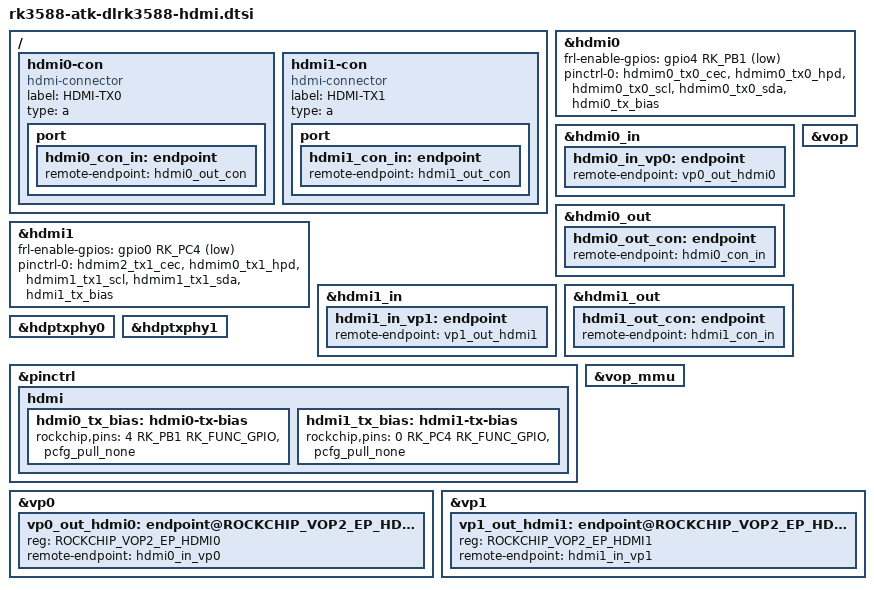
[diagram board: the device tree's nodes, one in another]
// SPDX-License-Identifier: (GPL-2.0+ OR MIT)
/*
 * ATK-DLRK3588 HDMI TX wiring, from the Alientek rk3588-atk-lcds.dtsi.
 * The vendor's enable-gpios controls the TMDS bias (high in TMDS mode,
 * low in FRL mode). Mainline models this as active-low frl-enable-gpios.
 */
#include <dt-bindings/soc/rockchip,vop2.h>

/ {
	hdmi0-con {
		compatible = "hdmi-connector";
		label = "HDMI-TX0";
		type = "a";

		port {
			hdmi0_con_in: endpoint {
				remote-endpoint = <&hdmi0_out_con>;
			};
		};
	};

	hdmi1-con {
		compatible = "hdmi-connector";
		label = "HDMI-TX1";
		type = "a";

		port {
			hdmi1_con_in: endpoint {
				remote-endpoint = <&hdmi1_out_con>;
			};
		};
	};
};

&hdmi0 {
	frl-enable-gpios = <&gpio4 RK_PB1 GPIO_ACTIVE_LOW>;
	pinctrl-0 = <&hdmim0_tx0_cec &hdmim0_tx0_hpd
		     &hdmim0_tx0_scl &hdmim0_tx0_sda &hdmi0_tx_bias>;
	status = "okay";
};

&hdmi0_in {
	hdmi0_in_vp0: endpoint {
		remote-endpoint = <&vp0_out_hdmi0>;
	};
};

&hdmi0_out {
	hdmi0_out_con: endpoint {
		remote-endpoint = <&hdmi0_con_in>;
	};
};

&hdmi1 {
	frl-enable-gpios = <&gpio0 RK_PC4 GPIO_ACTIVE_LOW>;
	pinctrl-0 = <&hdmim2_tx1_cec &hdmim0_tx1_hpd
		     &hdmim1_tx1_scl &hdmim1_tx1_sda &hdmi1_tx_bias>;
	status = "okay";
};

&hdmi1_in {
	hdmi1_in_vp1: endpoint {
		remote-endpoint = <&vp1_out_hdmi1>;
	};
};

&hdmi1_out {
	hdmi1_out_con: endpoint {
		remote-endpoint = <&hdmi1_con_in>;
	};
};

&hdptxphy0 {
	status = "okay";
};

&hdptxphy1 {
	status = "okay";
};

&pinctrl {
	hdmi {
		hdmi0_tx_bias: hdmi0-tx-bias {
			rockchip,pins = <4 RK_PB1 RK_FUNC_GPIO &pcfg_pull_none>;
		};

		hdmi1_tx_bias: hdmi1-tx-bias {
			rockchip,pins = <0 RK_PC4 RK_FUNC_GPIO &pcfg_pull_none>;
		};
	};
};

&vop {
	status = "okay";
};

&vop_mmu {
	status = "okay";
};

&vp0 {
	vp0_out_hdmi0: endpoint@ROCKCHIP_VOP2_EP_HDMI0 {
		reg = <ROCKCHIP_VOP2_EP_HDMI0>;
		remote-endpoint = <&hdmi0_in_vp0>;
	};
};

&vp1 {
	vp1_out_hdmi1: endpoint@ROCKCHIP_VOP2_EP_HDMI1 {
		reg = <ROCKCHIP_VOP2_EP_HDMI1>;
		remote-endpoint = <&hdmi1_in_vp1>;
	};
};
